# N32H487 register map
Vendor: Nationstech Ltd.; File version: 1.0
Registers are 32-bit, read-write, reset 0x0 unless marked. A register's access mark holds for its fields unless they carry their own. Offsets are from the block's base; [hi:lo] are bit positions; {n}, {i} and the like mark numbered series.

## ETH
Base 0x40025000
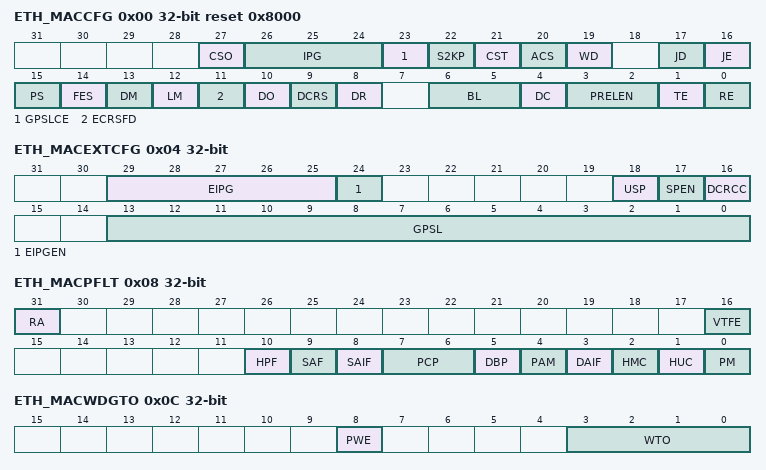
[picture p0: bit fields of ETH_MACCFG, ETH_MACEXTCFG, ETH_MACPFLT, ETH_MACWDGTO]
0x00 ETH_MACCFG reset 0x8000
  [27] CSO, [26:24] IPG, [23] GPSLCE, [22] S2KP, [21] CST, [20] ACS, [19] WD, [17] JD, [16] JE, [15] PS, [14] FES, [13] DM, [12] LM, [11] ECRSFD, [10] DO, [9] DCRS, [8] DR, [6:5] BL, [4] DC, [3:2] PRELEN, [1] TE, [0] RE
0x04 ETH_MACEXTCFG
  [29:25] EIPG, [24] EIPGEN, [18] USP, [17] SPEN, [16] DCRCC, [13:0] GPSL
0x08 ETH_MACPFLT
  [31] RA, [16] VTFE, [10] HPF, [9] SAF, [8] SAIF, [7:6] PCP, [5] DBP, [4] PAM, [3] DAIF, [2] HMC, [1] HUC, [0] PM
0x0C ETH_MACWDGTO
  [8] PWE, [3:0] WTO
0x10 ETH_MACHASHTR0
  [31:0] HT31T0
0x14 ETH_MACHASHTR1
  [31:0] HT63T32
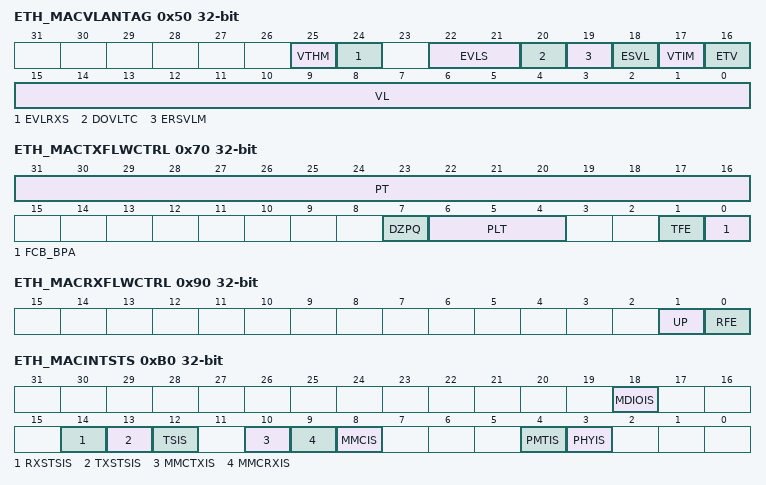
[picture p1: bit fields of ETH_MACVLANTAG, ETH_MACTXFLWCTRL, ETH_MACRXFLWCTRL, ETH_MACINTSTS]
0x50 ETH_MACVLANTAG
  [25] VTHM, [24] EVLRXS, [22:21] EVLS, [20] DOVLTC, [19] ERSVLM, [18] ESVL, [17] VTIM, [16] ETV, [15:0] VL
0x58 ETH_MACVHASHT
  [15:0] VLHT
0x70 ETH_MACTXFLWCTRL
  [31:16] PT, [7] DZPQ, [6:4] PLT, [1] TFE, [0] FCB_BPA
0x90 ETH_MACRXFLWCTRL
  [1] UP, [0] RFE
0xB0 ETH_MACINTSTS
  [18] MDIOIS, [14] RXSTSIS, [13] TXSTSIS, [12] TSIS, [10] MMCTXIS, [9] MMCRXIS, [8] MMCIS, [4] PMTIS, [3] PHYIS
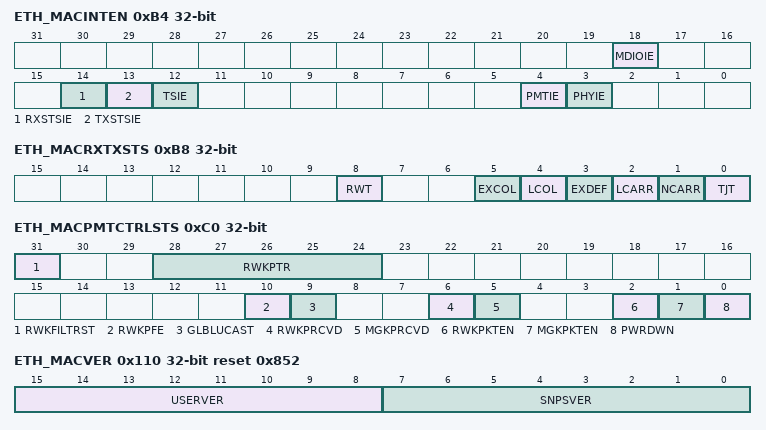
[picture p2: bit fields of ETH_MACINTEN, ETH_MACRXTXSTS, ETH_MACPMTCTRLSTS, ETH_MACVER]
0xB4 ETH_MACINTEN
  [18] MDIOIE, [14] RXSTSIE, [13] TXSTSIE, [12] TSIE, [4] PMTIE, [3] PHYIE
0xB8 ETH_MACRXTXSTS
  [8] RWT, [5] EXCOL, [4] LCOL, [3] EXDEF, [2] LCARR, [1] NCARR, [0] TJT
0xC0 ETH_MACPMTCTRLSTS
  [31] RWKFILTRST, [28:24] RWKPTR, [10] RWKPFE, [9] GLBLUCAST, [6] RWKPRCVD, [5] MGKPRCVD, [2] RWKPKTEN, [1] MGKPKTEN, [0] PWRDWN
0xC4 ETH_MACRWUPFLT
  [31:0] WKUPFRMFTR
0x110 ETH_MACVER reset 0x852
  [15:8] USERVER, [7:0] SNPSVER
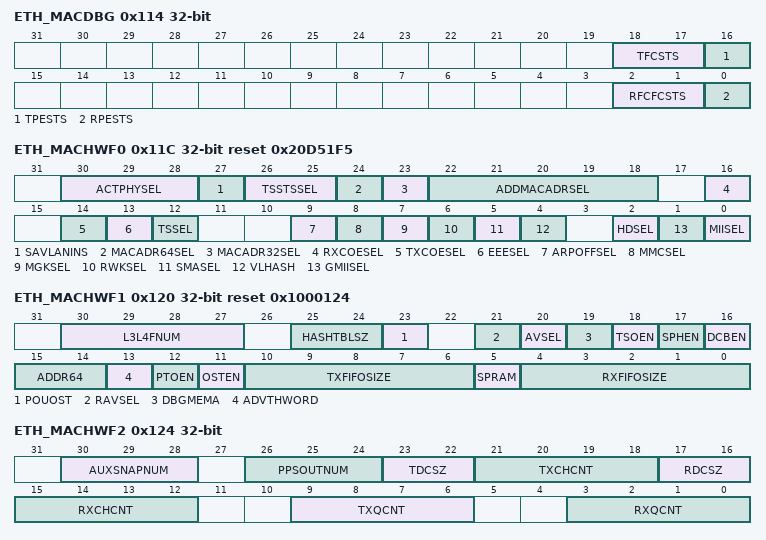
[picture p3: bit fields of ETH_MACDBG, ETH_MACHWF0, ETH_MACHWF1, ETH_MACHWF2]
0x114 ETH_MACDBG
  [18:17] TFCSTS, [16] TPESTS, [2:1] RFCFCSTS, [0] RPESTS
0x11C ETH_MACHWF0 reset 0x20D51F5
  [30:28] ACTPHYSEL, [27] SAVLANINS, [26:25] TSSTSSEL, [24] MACADR64SEL, [23] MACADR32SEL, [22:18] ADDMACADRSEL, [16] RXCOESEL, [14] TXCOESEL, [13] EEESEL, [12] TSSEL, [9] ARPOFFSEL, [8] MMCSEL, [7] MGKSEL, [6] RWKSEL, [5] SMASEL, [4] VLHASH, [2] HDSEL, [1] GMIISEL, [0] MIISEL
0x120 ETH_MACHWF1 reset 0x1000124
  [30:27] L3L4FNUM, [25:24] HASHTBLSZ, [23] POUOST, [21] RAVSEL, [20] AVSEL, [19] DBGMEMA, [18] TSOEN, [17] SPHEN, [16] DCBEN, [15:14] ADDR64, [13] ADVTHWORD, [12] PTOEN, [11] OSTEN, [10:6] TXFIFOSIZE, [5] SPRAM, [4:0] RXFIFOSIZE
0x124 ETH_MACHWF2
  [30:28] AUXSNAPNUM, [26:24] PPSOUTNUM, [23:22] TDCSZ, [21:18] TXCHCNT, [17:16] RDCSZ, [15:12] RXCHCNT, [9:6] TXQCNT, [3:0] RXQCNT
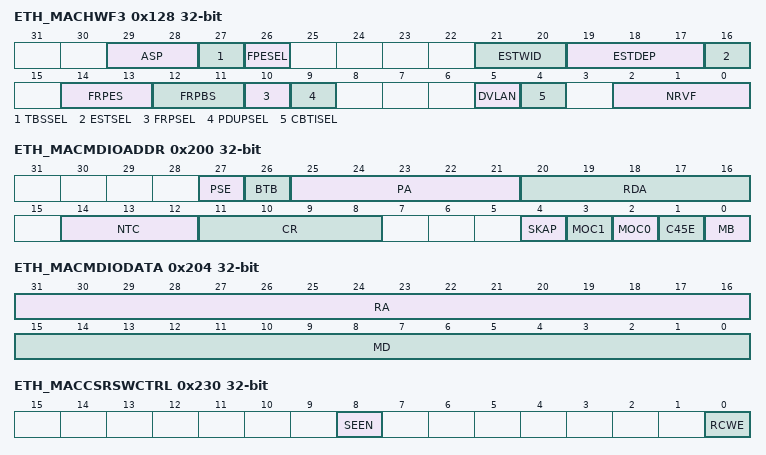
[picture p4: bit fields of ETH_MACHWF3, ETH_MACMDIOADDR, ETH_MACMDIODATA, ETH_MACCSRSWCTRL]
0x128 ETH_MACHWF3
  [29:28] ASP, [27] TBSSEL, [26] FPESEL, [21:20] ESTWID, [19:17] ESTDEP, [16] ESTSEL, [14:13] FRPES, [12:11] FRPBS, [10] FRPSEL, [9] PDUPSEL, [5] DVLAN, [4] CBTISEL, [2:0] NRVF
0x200 ETH_MACMDIOADDR
  [27] PSE, [26] BTB, [25:21] PA, [20:16] RDA, [14:12] NTC, [11:8] CR, [4] SKAP, [3] MOC1, [2] MOC0, [1] C45E, [0] MB
0x204 ETH_MACMDIODATA
  [31:16] RA, [15:0] MD
0x230 ETH_MACCSRSWCTRL
  [8] SEEN, [0] RCWE
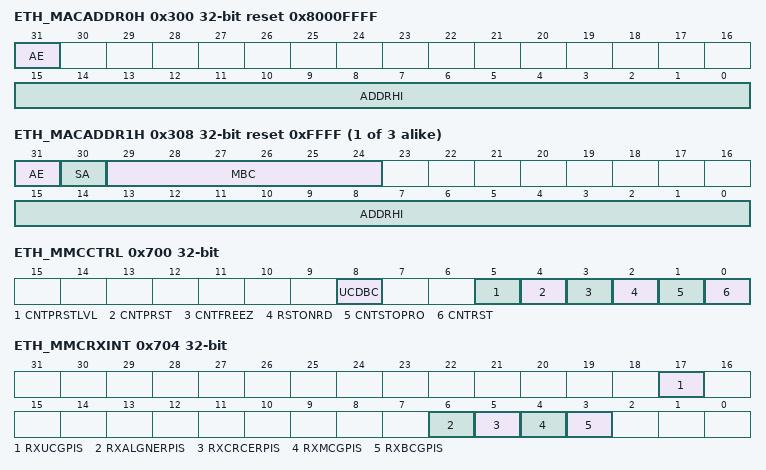
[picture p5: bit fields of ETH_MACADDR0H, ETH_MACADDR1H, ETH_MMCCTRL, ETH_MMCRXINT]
0x300 ETH_MACADDR0H reset 0x8000FFFF
  [31] AE, [15:0] ADDRHI
{0x304+8i} ETH_MACADDR{i}L reset 0xFFFFFFFF (i=0..3)
  [31:0] ADDRLO
{0x300+8i} ETH_MACADDR{i}H reset 0xFFFF (i=1..3)
  [31] AE, [30] SA, [29:24] MBC, [15:0] ADDRHI
0x700 ETH_MMCCTRL
  [8] UCDBC, [5] CNTPRSTLVL, [4] CNTPRST, [3] CNTFREEZ, [2] RSTONRD, [1] CNTSTOPRO, [0] CNTRST
0x704 ETH_MMCRXINT
  [17] RXUCGPIS, [6] RXALGNERPIS, [5] RXCRCERPIS, [4] RXMCGPIS, [3] RXBCGPIS
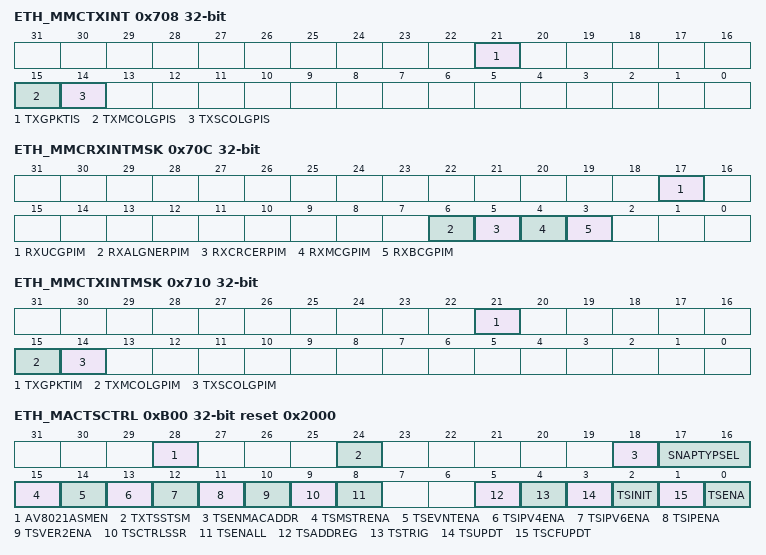
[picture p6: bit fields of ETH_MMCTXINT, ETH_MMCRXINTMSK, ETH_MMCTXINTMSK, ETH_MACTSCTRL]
0x708 ETH_MMCTXINT
  [21] TXGPKTIS, [15] TXMCOLGPIS, [14] TXSCOLGPIS
0x70C ETH_MMCRXINTMSK
  [17] RXUCGPIM, [6] RXALGNERPIM, [5] RXCRCERPIM, [4] RXMCGPIM, [3] RXBCGPIM
0x710 ETH_MMCTXINTMSK
  [21] TXGPKTIM, [15] TXMCOLGPIM, [14] TXSCOLGPIM
0x74C ETH_MMCTXSCGP
  [31:0] TXSNGLCOLG
0x750 ETH_MMCTXMCGP
  [31:0] TXMULTCOLG
0x768 ETH_MMCTXPCG
  [31:0] TXPKTG
0x78C ETH_MMCRXBPG
  [31:0] RXBCASTG
0x790 ETH_MMCRXMPG
  [31:0] RXMCASTG
0x794 ETH_MMCRXCRCEP
  [31:0] RXCRCERR
0x798 ETH_MMCRXAEP
  [31:0] RXALGNERR
0x7C4 ETH_MMCRXUPG
  [31:0] RXUCASTG
0xB00 ETH_MACTSCTRL reset 0x2000
  [28] AV8021ASMEN, [24] TXTSSTSM, [18] TSENMACADDR, [17:16] SNAPTYPSEL, [15] TSMSTRENA, [14] TSEVNTENA, [13] TSIPV4ENA, [12] TSIPV6ENA, [11] TSIPENA, [10] TSVER2ENA, [9] TSCTRLSSR, [8] TSENALL, [5] TSADDREG, [4] TSTRIG, [3] TSUPDT, [2] TSINIT, [1] TSCFUPDT, [0] TSENA
0xB04 ETH_MACSUBSINC
  [23:16] SSINC
0xB08 ETH_MACSYSTS
  [31:0] TSS
0xB0C ETH_MACSYSTNS
  [31:0] TSS
0xB10 ETH_MACSYSTSUP
  [31:0] TSS
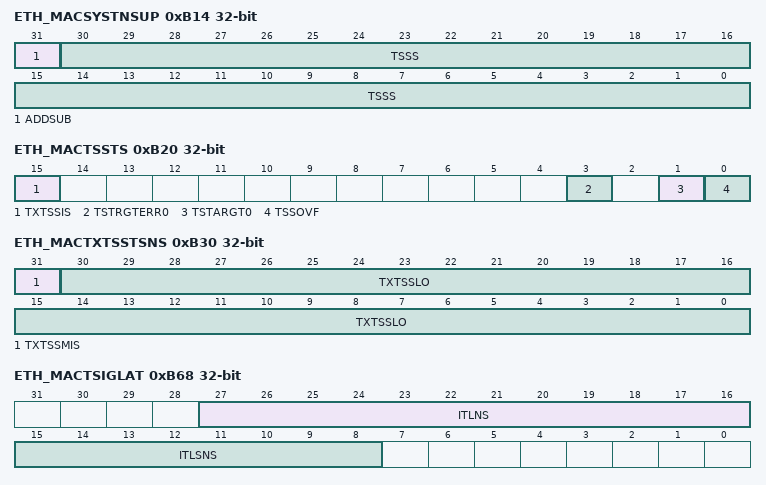
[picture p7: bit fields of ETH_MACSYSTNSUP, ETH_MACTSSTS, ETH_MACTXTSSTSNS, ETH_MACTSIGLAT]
0xB14 ETH_MACSYSTNSUP
  [31] ADDSUB, [30:0] TSSS
0xB18 ETH_MACTSADD
  [31:0] TSAR
0xB20 ETH_MACTSSTS
  [15] TXTSSIS, [3] TSTRGTERR0, [1] TSTARGT0, [0] TSSOVF
0xB30 ETH_MACTXTSSTSNS
  [31] TXTSSMIS, [30:0] TXTSSLO
0xB34 ETH_MACTXTSSTSS
  [31:0] TXTSSHI
0xB58 ETH_MACTSIGCNS
  [31:0] TSIC
0xB5C ETH_MACTSEGCNS
  [31:0] TSEC
0xB68 ETH_MACTSIGLAT
  [27:16] ITLNS, [15:8] ITLSNS
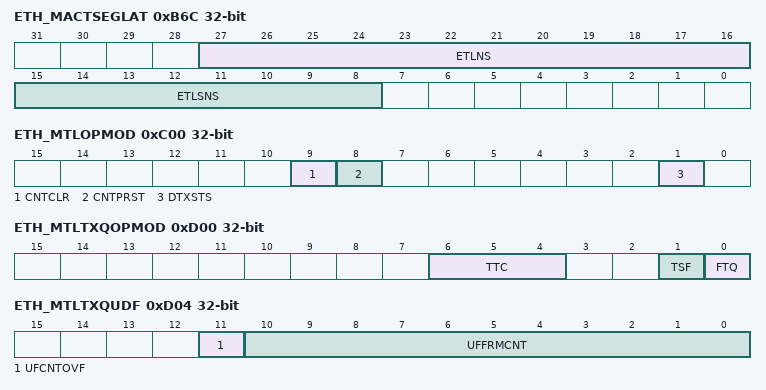
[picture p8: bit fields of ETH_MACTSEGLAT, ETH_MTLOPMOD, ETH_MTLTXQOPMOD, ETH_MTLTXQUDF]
0xB6C ETH_MACTSEGLAT
  [27:16] ETLNS, [15:8] ETLSNS
0xB70 ETH_MACPPSCTRL
  [3:0] PPSCTRL
0xB80 ETH_MACPPSTTS
  [31:0] TSTRH0
0xB84 ETH_MACPPSTTNS
  [30:0] TTSL0
0xC00 ETH_MTLOPMOD
  [9] CNTCLR, [8] CNTPRST, [1] DTXSTS
0xC20 ETH_MTLINTSTS
  [0] Q0IS
0xD00 ETH_MTLTXQOPMOD
  [6:4] TTC, [1] TSF, [0] FTQ
0xD04 ETH_MTLTXQUDF
  [11] UFCNTOVF, [10:0] UFFRMCNT
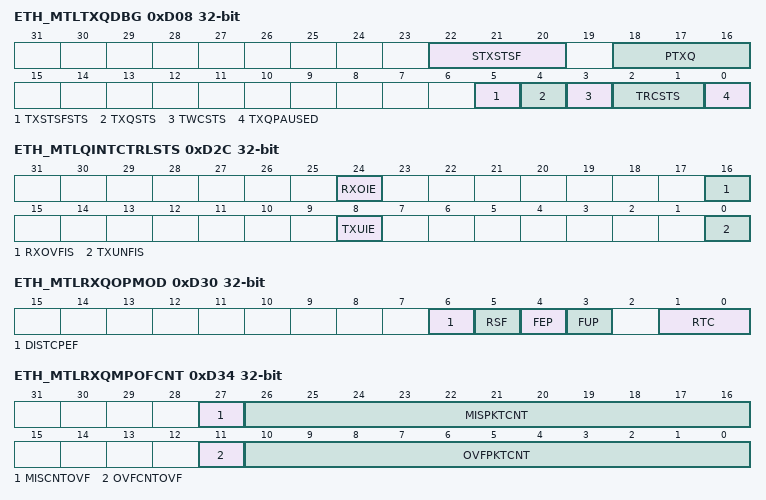
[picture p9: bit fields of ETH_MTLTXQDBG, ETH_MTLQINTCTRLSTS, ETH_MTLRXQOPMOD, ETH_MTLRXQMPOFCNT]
0xD08 ETH_MTLTXQDBG
  [22:20] STXSTSF, [18:16] PTXQ, [5] TXSTSFSTS, [4] TXQSTS, [3] TWCSTS, [2:1] TRCSTS, [0] TXQPAUSED
0xD2C ETH_MTLQINTCTRLSTS
  [24] RXOIE, [16] RXOVFIS, [8] TXUIE, [0] TXUNFIS
0xD30 ETH_MTLRXQOPMOD
  [6] DISTCPEF, [5] RSF, [4] FEP, [3] FUP, [1:0] RTC
0xD34 ETH_MTLRXQMPOFCNT
  [27] MISCNTOVF, [26:16] MISPKTCNT, [11] OVFCNTOVF, [10:0] OVFPKTCNT
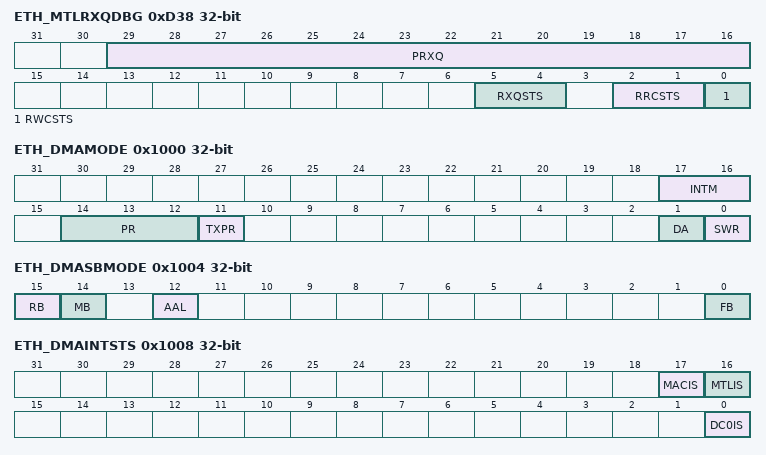
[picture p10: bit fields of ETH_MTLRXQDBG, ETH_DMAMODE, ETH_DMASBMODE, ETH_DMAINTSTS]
0xD38 ETH_MTLRXQDBG
  [29:16] PRXQ, [5:4] RXQSTS, [2:1] RRCSTS, [0] RWCSTS
0x1000 ETH_DMAMODE
  [17:16] INTM, [14:12] PR, [11] TXPR, [1] DA, [0] SWR
0x1004 ETH_DMASBMODE
  [15] RB, [14] MB, [12] AAL, [0] FB
0x1008 ETH_DMAINTSTS
  [17] MACIS, [16] MTLIS, [0] DC0IS
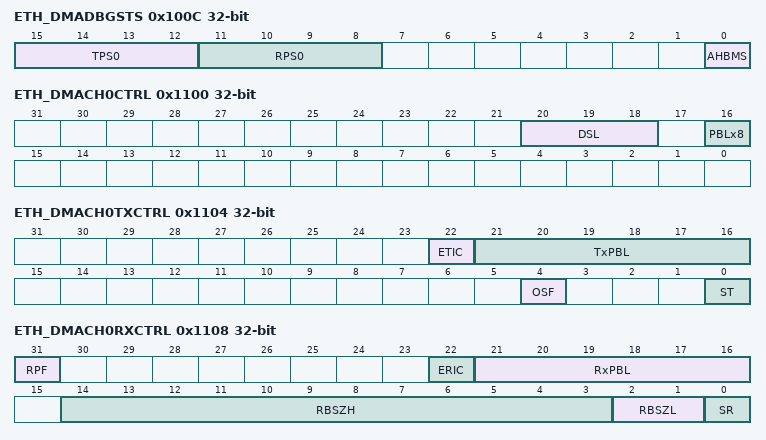
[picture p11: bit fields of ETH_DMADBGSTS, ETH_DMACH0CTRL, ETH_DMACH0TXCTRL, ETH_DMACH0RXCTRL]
0x100C ETH_DMADBGSTS
  [15:12] TPS0, [11:8] RPS0, [0] AHBMS
0x1100 ETH_DMACH0CTRL
  [20:18] DSL, [16] PBLx8
0x1104 ETH_DMACH0TXCTRL
  [22] ETIC, [21:16] TxPBL, [4] OSF, [0] ST
0x1108 ETH_DMACH0RXCTRL
  [31] RPF, [22] ERIC, [21:16] RxPBL, [14:3] RBSZH, [2:1] RBSZL, [0] SR
0x1114 ETH_DMACH0TXDLA
  [31:0] TDESLA
0x111C ETH_DMACH0RXDLA
  [31:0] RDESLA
0x1120 ETH_DMACH0TXDTP
  [31:0] TDTP
0x1128 ETH_DMACH0RXDTP
  [31:0] RDTP
0x112C ETH_DMACH0TXDRLEN
  [9:0] TDRL
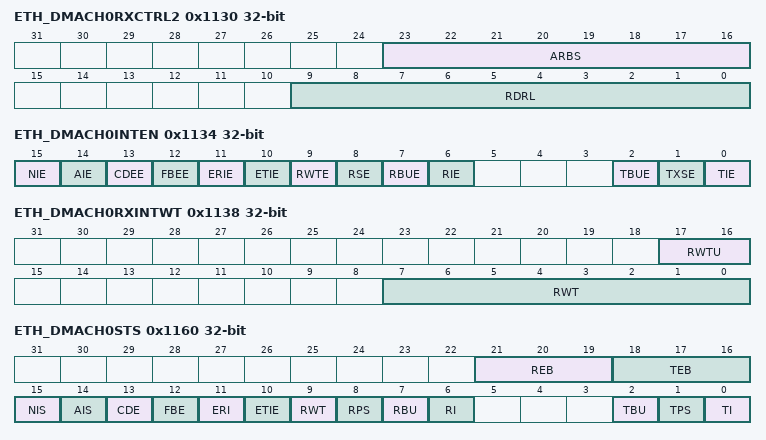
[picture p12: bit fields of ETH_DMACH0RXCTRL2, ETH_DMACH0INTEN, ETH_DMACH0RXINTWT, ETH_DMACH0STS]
0x1130 ETH_DMACH0RXCTRL2
  [23:16] ARBS, [9:0] RDRL
0x1134 ETH_DMACH0INTEN
  [15] NIE, [14] AIE, [13] CDEE, [12] FBEE, [11] ERIE, [10] ETIE, [9] RWTE, [8] RSE, [7] RBUE, [6] RIE, [2] TBUE, [1] TXSE, [0] TIE
0x1138 ETH_DMACH0RXINTWT
  [17:16] RWTU, [7:0] RWT
0x1144 ETH_DMACH0CATXD
  [31:0] CURTDESAPTR
0x114C ETH_DMACH0CARXD
  [31:0] CURRDESAPTR
0x1154 ETH_DMACH0CATXB
  [31:0] CURTBUFAPTR
0x115C ETH_DMACH0CARXB
  [31:0] CURRBUFAPTR
0x1160 ETH_DMACH0STS
  [21:19] REB, [18:16] TEB, [15] NIS, [14] AIS, [13] CDE, [12] FBE, [11] ERI, [10] ETIE, [9] RWT, [8] RPS, [7] RBU, [6] RI, [2] TBU, [1] TPS, [0] TI
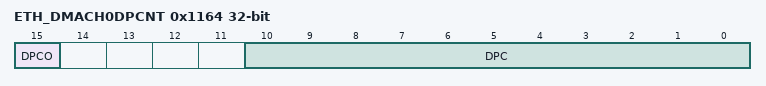
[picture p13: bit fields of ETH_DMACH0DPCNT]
0x1164 ETH_DMACH0DPCNT
  [15] DPCO, [10:0] DPC
0x116C ETH_DMACH0RXERICNT
  [11:0] ECNT
